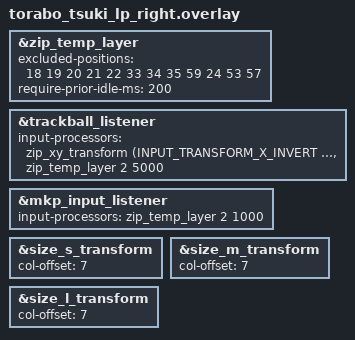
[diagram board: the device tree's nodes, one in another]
#include "torabo_tsuki_lp.dtsi"
#include <input/processors.dtsi>
#include <dt-bindings/zmk/input_transform.h>

&zip_temp_layer {
    excluded-positions = <
        18 19 20 21 22  /* Y-P */
        33 34 35  /* J - L */
        59  /* 右手親指 &kp LS(LA(TAB)) */
        24 53 57 /* 左手 LCTRL LALT LGUI */
    >;

    /* キー入力があるとこの期間は AML を発動しない (ミスタッチ防止) */
    require-prior-idle-ms = <200>;
}

&trackball_listener {
    input-processors = <
        &zip_xy_transform (INPUT_TRANSFORM_X_INVERT | INPUT_TRANSFORM_Y_INVERT)
        /* AML を有効化 (layer 2に移行)、5秒間 */
        &zip_temp_layer 2 5000
    >;
};

&mkp_input_listener {
    /* マウスボタン入力で5秒間layer 2に移行 */
    input-processors = <&zip_temp_layer 2 1000>;
}

&size_s_transform {
    col-offset = <7>;
};

&size_m_transform {
    col-offset = <7>;
};

&size_l_transform {
    col-offset = <7>;
};
